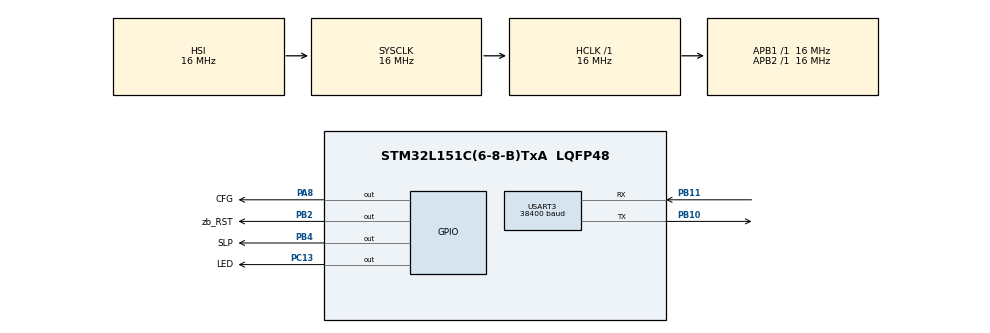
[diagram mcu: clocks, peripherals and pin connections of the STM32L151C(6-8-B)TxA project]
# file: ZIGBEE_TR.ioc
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Dma.Request0=USART3_RX
Dma.Request1=USART3_TX
Dma.USART3_RX.0.Direction=DMA_PERIPH_TO_MEMORY
Dma.USART3_RX.0.Instance=DMA1_Channel3
Dma.USART3_RX.0.MemDataAlignment=DMA_MDATAALIGN_BYTE
Dma.USART3_RX.0.MemInc=DMA_MINC_ENABLE
Dma.USART3_RX.0.Mode=DMA_NORMAL
Dma.USART3_RX.0.PeriphDataAlignment=DMA_PDATAALIGN_BYTE
Dma.USART3_RX.0.PeriphInc=DMA_PINC_DISABLE
Dma.USART3_RX.0.Priority=DMA_PRIORITY_LOW
Dma.USART3_TX.1.Direction=DMA_MEMORY_TO_PERIPH
Dma.USART3_TX.1.Instance=DMA1_Channel2
Dma.USART3_TX.1.MemDataAlignment=DMA_MDATAALIGN_BYTE
Dma.USART3_TX.1.MemInc=DMA_MINC_ENABLE
Dma.USART3_TX.1.Mode=DMA_NORMAL
Dma.USART3_TX.1.PeriphDataAlignment=DMA_PDATAALIGN_BYTE
Dma.USART3_TX.1.PeriphInc=DMA_PINC_DISABLE
Dma.USART3_TX.1.Priority=DMA_PRIORITY_LOW
Mcu.Family=STM32L1
Mcu.Name=STM32L151C(6-8-B)TxA
Mcu.Package=LQFP48
NVIC.DMA1_Channel2_IRQn=true\:1\:0\:true\:false\:true\:false\:true\:true
NVIC.DMA1_Channel3_IRQn=true\:1\:0\:true\:false\:true\:false\:true\:true
NVIC.PriorityGroup=NVIC_PRIORITYGROUP_4
NVIC.USART3_IRQn=true\:1\:0\:true\:false\:true\:false\:true\:true
PA13.Mode=Serial_Wire
PA13.Signal=SYS_JTMS-SWDIO
PA14.Mode=Serial_Wire
PA14.Signal=SYS_JTCK-SWCLK
PA8.GPIO_Label=CFG
PA8.PinState=GPIO_PIN_SET
PA8.Signal=GPIO_Output
PB10.Mode=Asynchronous
PB10.Signal=USART3_TX
PB11.Mode=Asynchronous
PB11.Signal=USART3_RX
PB2.GPIO_Label=zb_RST
PB2.PinState=GPIO_PIN_SET
PB2.Signal=GPIO_Output
PB4.GPIO_Label=SLP
PB4.PinState=GPIO_PIN_SET
PB4.Signal=GPIO_Output
PC13-WKUP2.GPIO_Label=LED
PC13-WKUP2.GPIO_ModeDefaultOutputPP=GPIO_MODE_OUTPUT_OD
PC13-WKUP2.GPIO_PuPd=GPIO_NOPULL
PC13-WKUP2.Signal=GPIO_Output
ProjectManager.HeapSize=0x200
ProjectManager.StackSize=0x400
ProjectManager.TargetToolchain=MDK-ARM V5.32
RCC.AHBFreq_Value=16000000
RCC.APB1Freq_Value=16000000
RCC.APB1TimFreq_Value=16000000
RCC.APB2Freq_Value=16000000
RCC.APB2TimFreq_Value=16000000
RCC.HCLKFreq_Value=16000000
RCC.HSE_VALUE=24000000
RCC.HSI_VALUE=16000000
RCC.LSE_VALUE=32768
RCC.MSI_VALUE=2097000
RCC.SYSCLKFreq_VALUE=16000000
RCC.SYSCLKSource=RCC_SYSCLKSOURCE_HSI
RCC.VCOOutputFreq_Value=48000000
USART3.BaudRate=38400
USART3.VirtualMode=VM_ASYNC
board=custom

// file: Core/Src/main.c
/* USER CODE BEGIN Header */
/**
 ******************************************************************************
 * @file           : main.c
 * @brief          : Main program body
 ******************************************************************************
 * @attention
 *
 * Copyright (c) 2026 STMicroelectronics.
 * All rights reserved.
 *
 * This software is licensed under terms that can be found in the LICENSE file
 * in the root directory of this software component.
 * If no LICENSE file comes with this software, it is provided AS-IS.
 *
 ******************************************************************************
 */
/* USER CODE END Header */
#include "main.h"
#include "dma.h"
#include "usart.h"
#include "gpio.h"

/* USER CODE BEGIN Includes */
#include "zigbee.h"
/* USER CODE END Includes */

/* USER CODE BEGIN PD */
#define tx_len 4
/* USER CODE END PD */

/* USER CODE BEGIN PV */
uint8_t tx_buffer[tx_len] = {0x00, 0x00, 0x10, 0x20};
/* USER CODE END PV */

void SystemClock_Config(void);

int main(void)
{

    /* MCU Configuration--------------------------------------------------------*/

    /* Reset of all peripherals, Initializes the Flash interface and the Systick. */
    HAL_Init();

    /* Configure the system clock */
    SystemClock_Config();

    /* Initialize all configured peripherals */
    MX_GPIO_Init();
    MX_DMA_Init();
    MX_USART3_UART_Init();
    /* USER CODE BEGIN 2 */
		HAL_Delay(500);
    Zigbee_CFGinit(Termminal);
    HAL_Delay(1000); // 等待联网
    /* USER CODE END 2 */

    /* Infinite loop */
    /* USER CODE BEGIN WHILE */
    while (1)
    {
        HAL_UART_Transmit_DMA(&huart3, tx_buffer, tx_len);
        // 2 秒等待期间 LED 闪烁
        for (uint8_t i = 0; i < 10; i++) // 每次闪烁周期 200ms * 10 = 2s
        {
            led_on;
            HAL_Delay(100);
            led_off;
            HAL_Delay(100);
        }
        /* USER CODE END WHILE */

    }
}

void SystemClock_Config(void)
{
    RCC_OscInitTypeDef RCC_OscInitStruct = {0};
    RCC_ClkInitTypeDef RCC_ClkInitStruct = {0};

    /** Configure the main internal regulator output voltage
     */
    __HAL_PWR_VOLTAGESCALING_CONFIG(PWR_REGULATOR_VOLTAGE_SCALE1);

    /** Initializes the RCC Oscillators according to the specified parameters
     * in the RCC_OscInitTypeDef structure.
     */
    RCC_OscInitStruct.OscillatorType = RCC_OSCILLATORTYPE_HSI;
    RCC_OscInitStruct.HSIState = RCC_HSI_ON;
    RCC_OscInitStruct.HSICalibrationValue = RCC_HSICALIBRATION_DEFAULT;
    RCC_OscInitStruct.PLL.PLLState = RCC_PLL_NONE;
    if (HAL_RCC_OscConfig(&RCC_OscInitStruct) != HAL_OK)
    {
        Error_Handler();
    }

    /** Initializes the CPU, AHB and APB buses clocks
     */
    RCC_ClkInitStruct.ClockType = RCC_CLOCKTYPE_HCLK | RCC_CLOCKTYPE_SYSCLK | RCC_CLOCKTYPE_PCLK1 | RCC_CLOCKTYPE_PCLK2;
    RCC_ClkInitStruct.SYSCLKSource = RCC_SYSCLKSOURCE_HSI;
    RCC_ClkInitStruct.AHBCLKDivider = RCC_SYSCLK_DIV1;
    RCC_ClkInitStruct.APB1CLKDivider = RCC_HCLK_DIV1;
    RCC_ClkInitStruct.APB2CLKDivider = RCC_HCLK_DIV1;

    if (HAL_RCC_ClockConfig(&RCC_ClkInitStruct, FLASH_LATENCY_0) != HAL_OK)
    {
        Error_Handler();
    }
}

void Error_Handler(void)
{
    __disable_irq();
    while (1)
    {
    }
}
